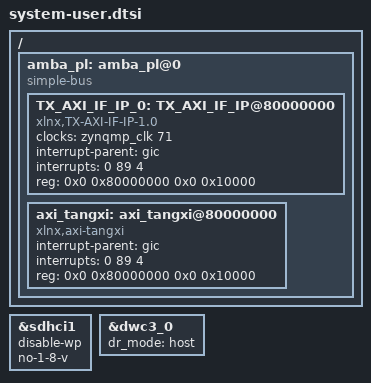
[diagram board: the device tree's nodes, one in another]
/include/ "system-conf.dtsi"
/ {
  amba_pl: amba_pl@0 {
    #address-cells = <2>;
    #size-cells = <2>;
    compatible = "simple-bus";
    ranges ;
    TX_AXI_IF_IP_0: TX_AXI_IF_IP@80000000 {
      clock-names = "clk";
      clocks = <&zynqmp_clk 71>;
      compatible = "xlnx,TX-AXI-IF-IP-1.0";
      interrupt-names = "TangXi_irq";
      interrupt-parent = <&gic>;
      interrupts = <0 89 4>;
      reg = <0x0 0x80000000 0x0 0x10000>;
    };
  };
};

/* SD */
&sdhci1 {
  disable-wp;
  no-1-8-v;
};

/* USB */
&dwc3_0 {
  status = "okay";
  dr_mode = "host";
};

&amba_pl {
  #address-cells = <2>;
  #size-cells = <2>;
  axi_tangxi: axi_tangxi@80000000 {
    compatible = "xlnx,axi-tangxi";
    interrupt-names = "axitangxi_irq";
    interrupt-parent = <&gic>;
    interrupts = <0 89 4>;
    reg = <0x0 0x80000000 0x0 0x10000>;
    };
};
